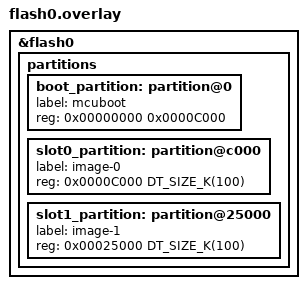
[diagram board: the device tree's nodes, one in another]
&flash0 {
	partitions {
    boot_partition: partition@0 {
      label = "mcuboot";
      reg = <0x00000000 0x0000C000>;
    };

    slot0_partition: partition@c000 {
      label = "image-0";
      reg = <0x0000C000 DT_SIZE_K(100)>;
    };

    slot1_partition: partition@25000 {
      label = "image-1";
      reg = <0x00025000 DT_SIZE_K(100)>;
    };
	};
};
